# M4G7 register map
File version: 0.1
Registers are 32-bit, read-write, reset 0x0 unless marked. A register's access mark holds for its fields unless they carry their own. Offsets are from the block's base; [hi:lo] are bit positions; {n}, {i} and the like mark numbered series.

## PC — Port C
Base 0x400E0200
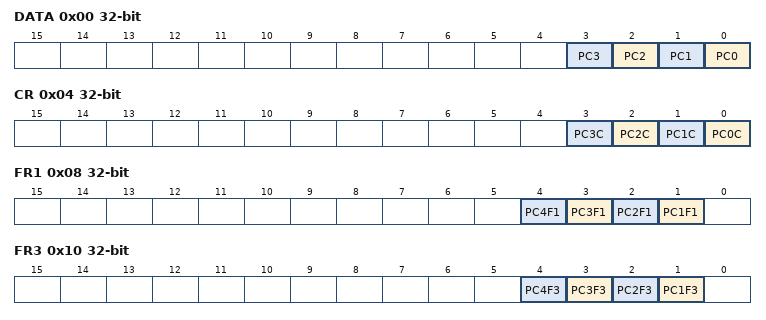
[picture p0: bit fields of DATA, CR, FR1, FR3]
0x00 DATA — Port C Data Register
  [n] PC{n} (n=0..3)
0x04 CR — Port C Output Control Register
  [n] PC{n}C (n=0..3)
0x08 FR1 — Port C Function Register 1
  [n] PC{n}F1 (n=1..4)
0x10 FR3 — Port C Function Register 3
  [n] PC{n}F3 (n=1..4)
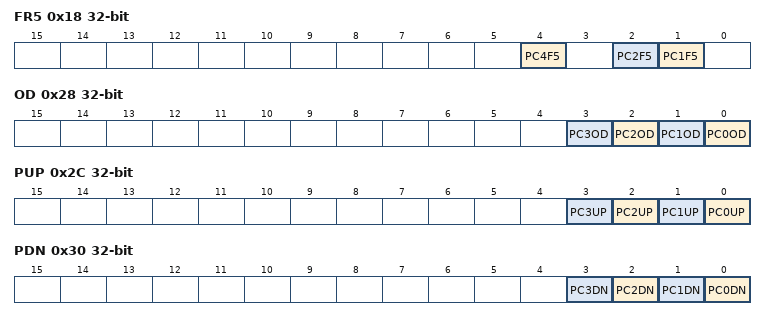
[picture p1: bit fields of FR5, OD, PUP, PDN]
0x18 FR5 — Port C Function Register 5
  [4] PC4F5, [2] PC2F5, [1] PC1F5
0x28 OD — Port C Open Drain Control Register
  [n] PC{n}OD (n=0..3)
0x2C PUP — Port C Pull-up Control Register
  [n] PC{n}UP (n=0..3)
0x30 PDN — Port C Pull-down Control Register
  [n] PC{n}DN (n=0..3)
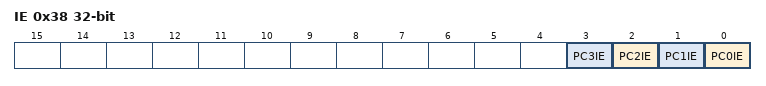
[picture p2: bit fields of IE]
0x38 IE — Port C Input Control Register
  [n] PC{n}IE (n=0..3)

## PD — Port D
Base 0x400E0300
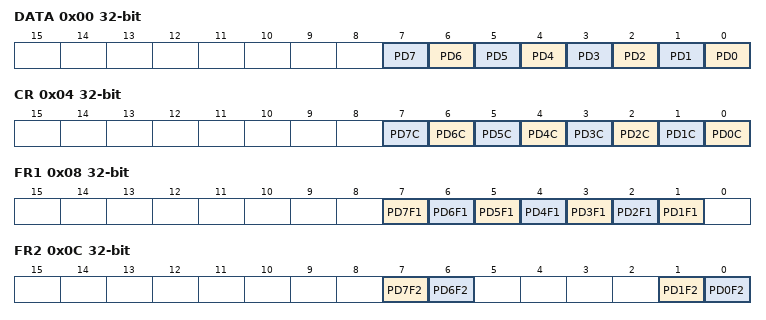
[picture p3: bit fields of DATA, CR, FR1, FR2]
0x00 DATA — Port D Data Register
  [n] PD{n} (n=0..7)
0x04 CR — Port D Output Control Register
  [n] PD{n}C (n=0..7)
0x08 FR1 — Port D Function Register 1
  [n] PD{n}F1 (n=1..7)
0x0C FR2 — Port D Function Register 2
  [7] PD7F2, [6] PD6F2, [1] PD1F2, [0] PD0F2
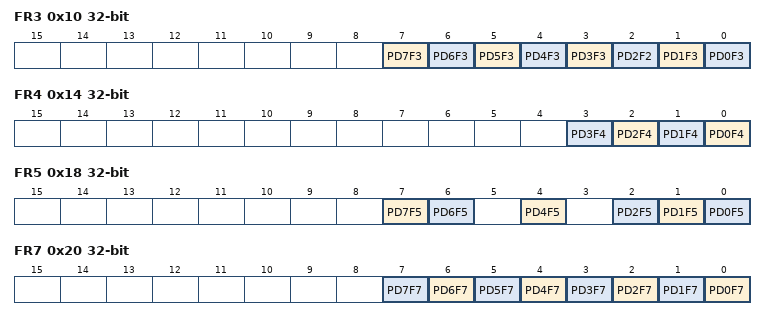
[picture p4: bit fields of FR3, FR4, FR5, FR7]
0x10 FR3 — Port D Function Register 3
  [n] PD{n}F3 (n=3..7), [2] PD2F2, [1] PD1F3, [0] PD0F3
0x14 FR4 — Port D Function Register 4
  [n] PD{n}F4 (n=0..3)
0x18 FR5 — Port D Function Register 5
  [7] PD7F5, [6] PD6F5, [4] PD4F5, [2] PD2F5, [1] PD1F5, [0] PD0F5
0x1C FR6 — Port D Function Register 6
  [0] PD0F6
0x20 FR7 — Port D Function Register 7
  [n] PD{n}F7 (n=0..7)
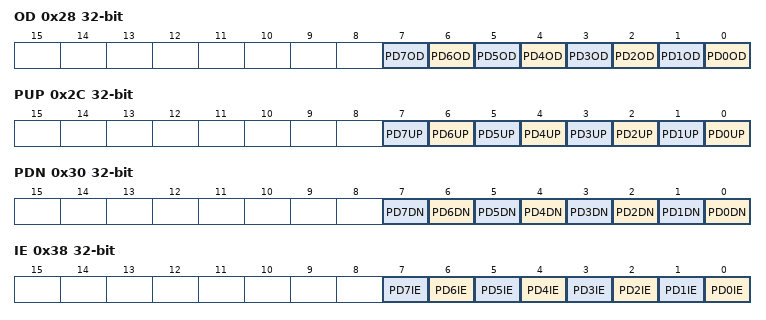
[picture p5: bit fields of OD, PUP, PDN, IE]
0x28 OD — Port D Open Drain Control Register
  [n] PD{n}OD (n=0..7)
0x2C PUP — Port D Pull-up Control Register
  [n] PD{n}UP (n=0..7)
0x30 PDN — Port D Pull-down Control Register
  [n] PD{n}DN (n=0..7)
0x38 IE — Port D Input Control Register
  [n] PD{n}IE (n=0..7)

## PE — Port E
Base 0x400E0400
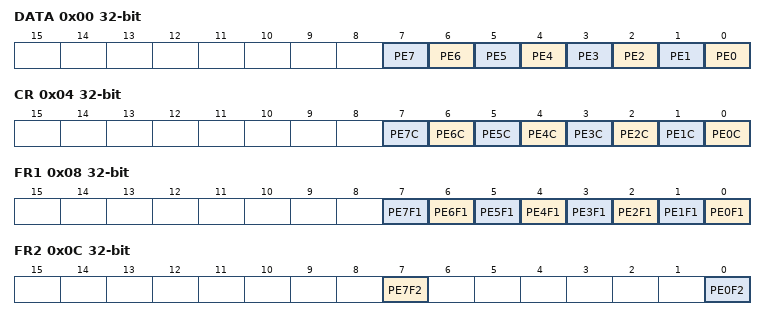
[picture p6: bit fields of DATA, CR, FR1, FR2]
0x00 DATA — Port E Data Register
  [n] PE{n} (n=0..7)
0x04 CR — Port E Output Control Register
  [n] PE{n}C (n=0..7)
0x08 FR1 — Port E Function Register 1
  [n] PE{n}F1 (n=0..7)
0x0C FR2 — Port E Function Register 2
  [7] PE7F2, [0] PE0F2
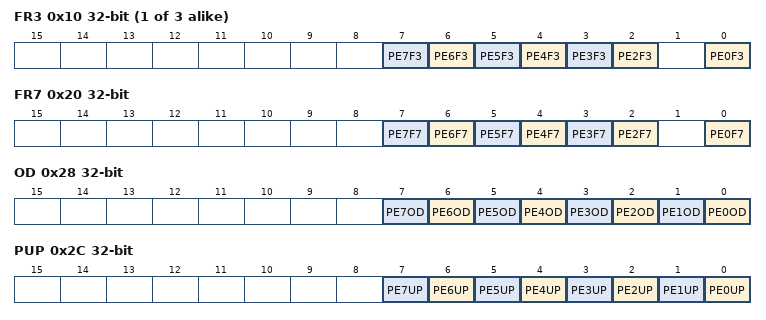
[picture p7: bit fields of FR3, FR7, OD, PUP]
{0x4+4i} FR{i} (i=3..5) — Port E Function Register {i}
  [n] PE{n}F{i} (n=2..7), [0] PE0F{i}
0x20 FR7 — Port E Function Register 7
  [n] PE{n}F7 (n=2..7), [0] PE0F7
0x28 OD — Port E Open Drain Control Register
  [n] PE{n}OD (n=0..7)
0x2C PUP — Port E Pull-up Control Register
  [n] PE{n}UP (n=0..7)
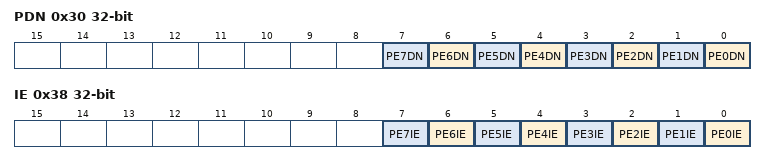
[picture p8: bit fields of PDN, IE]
0x30 PDN — Port E Pull-down Control Register
  [n] PE{n}DN (n=0..7)
0x38 IE — Port E Input Control Register
  [n] PE{n}IE (n=0..7)

## PF — Port F
Base 0x400E0500
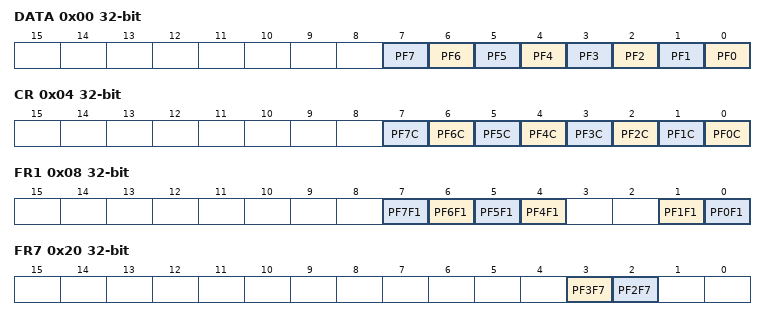
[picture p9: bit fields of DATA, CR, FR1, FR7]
0x00 DATA — Port F Data Register
  [n] PF{n} (n=0..7)
0x04 CR — Port F Output Control Register
  [n] PF{n}C (n=0..7)
0x08 FR1 — Port F Function Register 1
  [n] PF{n}F1 (n=4..7), [1] PF1F1, [0] PF0F1
0x20 FR7 — Port F Function Register 7
  [3] PF3F7, [2] PF2F7
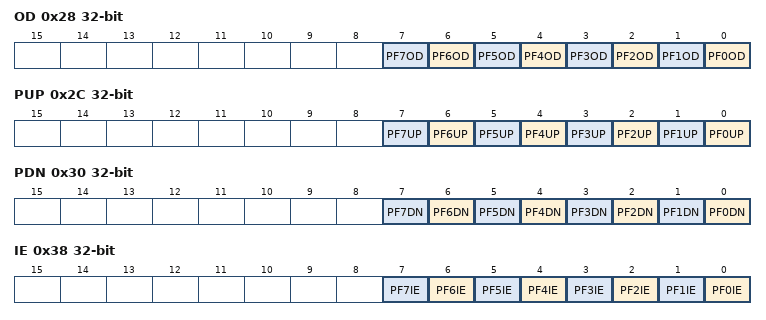
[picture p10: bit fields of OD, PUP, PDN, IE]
0x28 OD — Port F Open Drain Control Register
  [n] PF{n}OD (n=0..7)
0x2C PUP — Port F Pull-up Control Register
  [n] PF{n}UP (n=0..7)
0x30 PDN — Port F Pull-down Control Register
  [n] PF{n}DN (n=0..7)
0x38 IE — Port F Input Control Register
  [n] PF{n}IE (n=0..7)

## PG — Port G
Base 0x400E0600
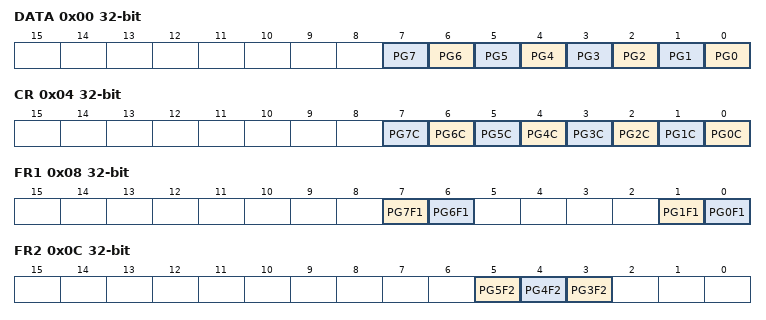
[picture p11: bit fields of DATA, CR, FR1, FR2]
0x00 DATA — Port G Data Register
  [n] PG{n} (n=0..7)
0x04 CR — Port G Output Control Register
  [n] PG{n}C (n=0..7)
0x08 FR1 — Port G Function Register 1
  [7] PG7F1, [6] PG6F1, [1] PG1F1, [0] PG0F1
0x0C FR2 — Port G Function Register 2
  [5] PG5F2, [4] PG4F2, [3] PG3F2
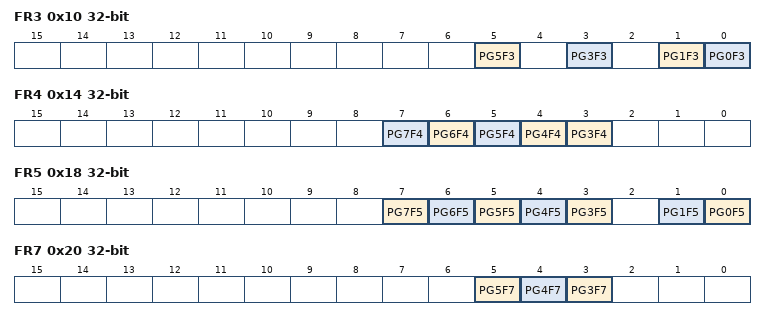
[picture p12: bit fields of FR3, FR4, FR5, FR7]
0x10 FR3 — Port G Function Register 3
  [5] PG5F3, [3] PG3F3 ro, [1] PG1F3 ro, [0] PG0F3 ro
0x14 FR4 — Port G Function Register 4
  [n] PG{n}F4 (n=4..7), [3] PG3F4 ro
0x18 FR5 — Port G Function Register 5
  [n] PG{n}F5 (n=3..7), [1] PG1F5, [0] PG0F5
0x20 FR7 — Port G Function Register 7
  [5] PG5F7, [4] PG4F7, [3] PG3F7
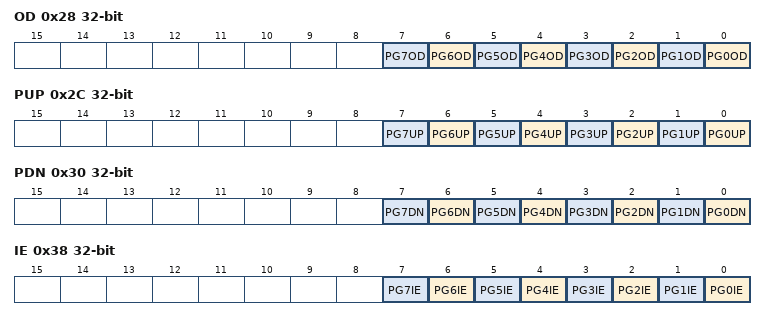
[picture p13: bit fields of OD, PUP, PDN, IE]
0x28 OD — Port G Open Drain Control Register
  [n] PG{n}OD (n=0..7)
0x2C PUP — Port G Pull-up Control Register
  [n] PG{n}UP (n=0..7)
0x30 PDN — Port G Pull-down Control Register
  [n] PG{n}DN (n=0..7)
0x38 IE — Port G Input Control Register
  [n] PG{n}IE (n=0..7)
